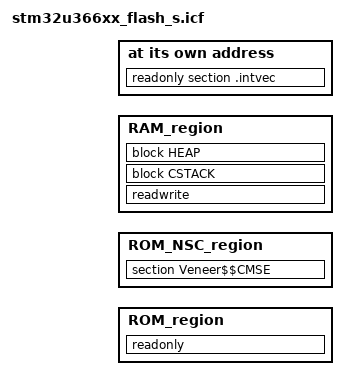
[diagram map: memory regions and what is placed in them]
/*###ICF### Section handled by ICF editor, don't touch! ****/
/*-Editor annotation file-*/
/* IcfEditorFile="$TOOLKIT_DIR$\config\ide\IcfEditor\cortex_v1_0.xml" */
/*-Specials-*/
/*************************************************************************************************/
#include "appli_region_defs.h"
/*************************************************************************************************/

define symbol ROM_S_START                  = S_CODE_START;
define symbol ROM_S_SIZE                   = S_CODE_SIZE;
define symbol ROM_S_END                    = (S_CODE_START + S_CODE_SIZE - 1);

define symbol ROM_NSC_START                = NSC_CODE_START;
define symbol ROM_NSC_END                  = (NSC_CODE_START + NSC_CODE_SIZE - 1);

define symbol RAM_S_START                  = S_RAM_START;
define symbol RAM_S_END                    = (S_RAM_START + S_RAM_SIZE - 1);

/*************************************************************************************************/
define symbol __ICFEDIT_intvec_start__     = ROM_S_START;
/*-Memory Regions-*/
define symbol __ICFEDIT_region_ROM_start__ = ROM_S_START;
define symbol __ICFEDIT_region_ROM_end__   = ROM_S_END;
define symbol __region_ROM_NSC_start__ 	   = ROM_NSC_START;
define symbol __region_ROM_NSC_end__       = ROM_NSC_END;
define symbol __ICFEDIT_region_RAM_start__ = RAM_S_START;
define symbol __ICFEDIT_region_RAM_end__   = RAM_S_END;

/*-Sizes-*/
define symbol __ICFEDIT_size_cstack__      = 0x400;
define symbol __ICFEDIT_size_heap__        = 0x200;
/**** End of ICF editor section. ###ICF###*/

define memory mem with size = 4G;

define region ROM_region      = mem:[from __ICFEDIT_region_ROM_start__ to __ICFEDIT_region_ROM_end__];
define region ROM_NSC_region  = mem:[from __region_ROM_NSC_start__     to __region_ROM_NSC_end__];
define region RAM_region      = mem:[from __ICFEDIT_region_RAM_start__ to __ICFEDIT_region_RAM_end__];

define block CSTACK    with alignment = 8, size = __ICFEDIT_size_cstack__   { };
define block HEAP      with alignment = 8, size = __ICFEDIT_size_heap__     { };

initialize by copy { readwrite };
do not initialize  { section .noinit };

place at address mem:__ICFEDIT_intvec_start__ { readonly section .intvec };

place in ROM_region     { readonly };
place in ROM_NSC_region { section Veneer$$CMSE };
place in RAM_region     { readwrite,
                          block CSTACK, block HEAP };
